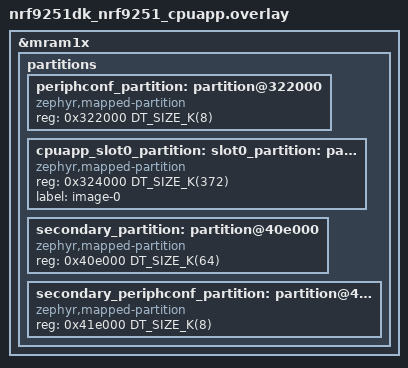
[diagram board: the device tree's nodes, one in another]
/*
 * Copyright (c) 2026 Nordic Semiconductor ASA
 *
 * SPDX-License-Identifier: LicenseRef-Nordic-5-Clause
 */

/* Delete the original partitions before redefining them */
/delete-node/ &cpuapp_slot0_partition;
/delete-node/ &periphconf_partition;

&mram1x {
	partitions {
		/* cpuapp_boot_partition is at 0x312000 with size 64KB (0x10000) */
		/* Move periphconf_partition to 0x322000 (right after cpuapp_boot_partition) */
		periphconf_partition: partition@322000 {
			compatible = "zephyr,mapped-partition";
			reg = <0x322000 DT_SIZE_K(8)>;
		};

		/* Move cpuapp_slot0_partition to start after periphconf_partition */
		/* periphconf_partition ends at 0x324000, so slot0 starts there and keeps
		 * its original end address, leaving cpuapp_slot1_partition untouched.
		 * The slot0_partition and label properties are reapplied here because
		 * the board devicetree adds them before this overlay is processed.
		 */
		cpuapp_slot0_partition: slot0_partition: partition@324000 {
			compatible = "zephyr,mapped-partition";
			reg = <0x324000 DT_SIZE_K(372)>;
			label = "image-0";
		};

		/* The nRF9251 DK memory map has no secondary firmware partitions,
		 * unlike the nRF54H20 DK, so add them here. CONFIG_GEN_UICR_SECONDARY
		 * reads secondary_partition to fill in UICR.SECONDARY.ADDRESS.
		 *
		 * These two nodes match the addresses and sizes the nRF9251 DK memory
		 * map is gaining, and can be dropped from this overlay once that lands.
		 * Redeclaring them here is a no-op in that case.
		 */
		secondary_partition: partition@40e000 {
			compatible = "zephyr,mapped-partition";
			reg = <0x40e000 DT_SIZE_K(64)>;
		};

		/* The secondary firmware boots in place of the primary, so the
		 * primary's periphconf_partition is never applied. Without its own
		 * PERIPHCONF the secondary's UART is never configured and it boots
		 * silently.
		 */
		secondary_periphconf_partition: partition@41e000 {
			compatible = "zephyr,mapped-partition";
			reg = <0x41e000 DT_SIZE_K(8)>;
		};
	};
};
